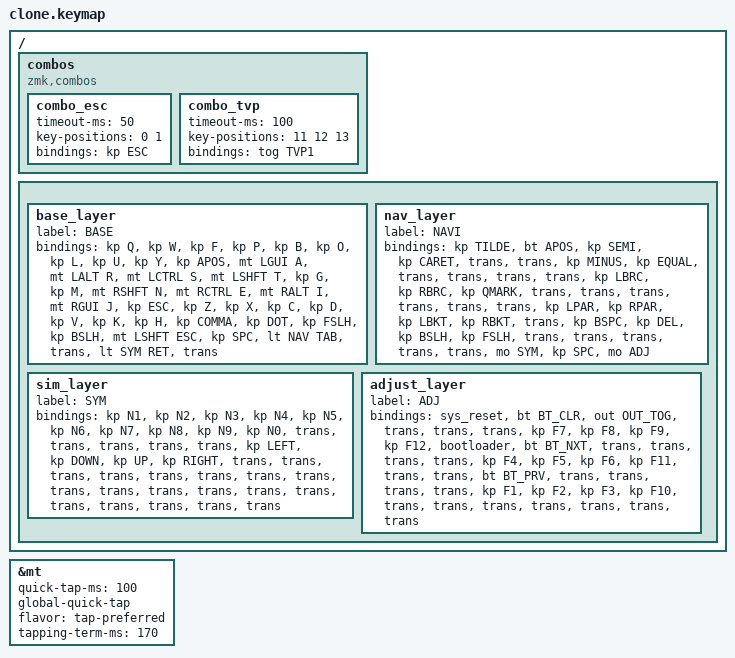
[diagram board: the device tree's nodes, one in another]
#include <behaviors.dtsi>
#include <dt-bindings/zmk/keys.h>
#include <dt-bindings/zmk/bt.h>
#include <dt-bindings/zmk/outputs.h>

#define BASE 0
#define NAV  1
#define SYM  2
#define ADJ  3
#define TVP1 4
#define TVP2 5

&mt {
    quick-tap-ms = <100>;
    global-quick-tap;
    flavor = "tap-preferred";
    tapping-term-ms = <170>;
};

/ {
    combos {
        compatible = "zmk,combos";
        combo_esc {
            timeout-ms = <50>;
            key-positions = <0 1>;
            bindings = <&kp ESC>;
        };
        combo_tvp {
            timeout-ms = <100>;
            key-positions = <11 12 13>;
            bindings = <&tog TVP1>;
        };
    };
    {
        base_layer {
            label= "BASE";

            //             ┏━━━━━━━━━━━┳━━━━━━━━━━━┳━━━━━━━━━━━┳━━━━━━━━━━━┳━━━━━━━━━━━┓   ┏━━━━━━━━━━━┳━━━━━━━━━━━┳━━━━━━━━━━━┳━━━━━━━━━━━┳━━━━━━━━━━━┓
            //             ┃     Q     ┃     W     ┃     F     ┃     P     ┃     B     ┃   ┃     O     ┃     L     ┃     U     ┃     Y     ┃    '/"    ┃
            //             ┣━━━━━━━━━━━╋━━━━━━━━━━━╋━━━━━━━━━━━╋━━━━━━━━━━━╋━━━━━━━━━━━┫   ┣━━━━━━━━━━━╋━━━━━━━━━━━╋━━━━━━━━━━━╋━━━━━━━━━━━╋━━━━━━━━━━━┫
            //             ┃     A     ┃     R     ┃     S     ┃     T     ┃     G     ┃   ┃     M     ┃     N     ┃     E     ┃     I     ┃     J     ┃
            // ┏━━━━━━━━━━━╋━━━━━━━━━━━╋━━━━━━━━━━━╋━━━━━━━━━━━╋━━━━━━━━━━━╋━━━━━━━━━━━┫   ┣━━━━━━━━━━━╋━━━━━━━━━━━╋━━━━━━━━━━━╋━━━━━━━━━━━╋━━━━━━━━━━━╋━━━━━━━━━━━┓
            // ┃    ESC    ┃     Z     ┃     X     ┃     C     ┃     D     ┃     V     ┃   ┃     K     ┃     H     ┃     ,     ┃     .     ┃     /     ┃     \     ┃
            // ┗━━━━━━━━━━━┻━━━━━━━━━━━┻━━━━━━━━━━━╋━━━━━━━━━━━╋━━━━━━━━━━━╋━━━━━━━━━━━┫   ┣━━━━━━━━━━━╋━━━━━━━━━━━╋━━━━━━━━━━━╋━━━━━━━━━━━┻━━━━━━━━━━━┻━━━━━━━━━━━┛
            //                                     ┃ LSHFT/ESC ┃    SPC    ┃   /TAB    ┃   ┃           ┃   /RET    ┃           ┃
            //                                     ┗━━━━━━━━━━━┻━━━━━━━━━━━┻━━━━━━━━━━━┛   ┗━━━━━━━━━━━┻━━━━━━━━━━━┻━━━━━━━━━━━┛
            bindings = <

                // ╷           ╷           ╷           ╷           ╷           ╷           ╷   ╷           ╷           ╷           ╷           ╷           ╷           ╷

                               &kp Q       &kp W       &kp F       &kp P       &kp B           &kp O       &kp L       &kp U       &kp Y       &kp APOS
                               &mt LGUI A  &mt LALT R  &mt LCTRL S &mt LSHFT T &kp G           &kp M       &mt RSHFT N &mt RCTRL E &mt RALT I  &mt RGUI J
                   &kp ESC     &kp Z       &kp X       &kp C       &kp D       &kp V           &kp K       &kp H       &kp COMMA   &kp DOT     &kp FSLH    &kp BSLH
                                                     &mt LSHFT ESC &kp SPC     &lt NAV TAB     &trans      &lt SYM RET &trans
            >;
        };

        nav_layer {
            label= "NAVI";

            //             ┏━━━━━━━━━━━┳━━━━━━━━━━━┳━━━━━━━━━━━┳━━━━━━━━━━━┳━━━━━━━━━━━┓   ┏━━━━━━━━━━━┳━━━━━━━━━━━┳━━━━━━━━━━━┳━━━━━━━━━━━┳━━━━━━━━━━━┓
            //             ┃     ~     ┃    '/"    ┃    ;/:    ┃     ^     ┃           ┃   ┃           ┃    -/_    ┃    =/+    ┃           ┃           ┃
            //             ┣━━━━━━━━━━━╋━━━━━━━━━━━╋━━━━━━━━━━━╋━━━━━━━━━━━╋━━━━━━━━━━━┫   ┣━━━━━━━━━━━╋━━━━━━━━━━━╋━━━━━━━━━━━╋━━━━━━━━━━━╋━━━━━━━━━━━┫
            //             ┃           ┃           ┃     {     ┃     }     ┃     ?     ┃   ┃           ┃           ┃           ┃           ┃           ┃
            // ┏━━━━━━━━━━━╋━━━━━━━━━━━╋━━━━━━━━━━━╋━━━━━━━━━━━╋━━━━━━━━━━━╋━━━━━━━━━━━┫   ┣━━━━━━━━━━━╋━━━━━━━━━━━╋━━━━━━━━━━━╋━━━━━━━━━━━╋━━━━━━━━━━━╋━━━━━━━━━━━┓
            // ┃           ┃     (     ┃     )     ┃     [     ┃     ]     ┃           ┃   ┃ BACKSPACE ┃  DELETE   ┃     \     ┃     /     ┃           ┃           ┃
            // ┗━━━━━━━━━━━┻━━━━━━━━━━━┻━━━━━━━━━━━╋━━━━━━━━━━━╋━━━━━━━━━━━╋━━━━━━━━━━━┫   ┣━━━━━━━━━━━╋━━━━━━━━━━━╋━━━━━━━━━━━╋━━━━━━━━━━━┻━━━━━━━━━━━┻━━━━━━━━━━━┛
            //                                     ┃           ┃           ┃           ┃   ┃     SYM   ┃   SPACE   ┃    ADJ    ┃
            //                                     ┗━━━━━━━━━━━┻━━━━━━━━━━━┻━━━━━━━━━━━┛   ┗━━━━━━━━━━━┻━━━━━━━━━━━┻━━━━━━━━━━━┛
            bindings = <
                // ╷           ╷           ╷           ╷           ╷           ╷           ╷   ╷           ╷           ╷           ╷           ╷           ╷           ╷

                                &kp TILDE   &bt APOS    &kp SEMI    &kp CARET   &trans          &trans      &kp MINUS   &kp EQUAL   &trans      &trans
                                &trans      &trans      &kp LBRC    &kp RBRC    &kp QMARK       &trans      &trans      &trans      &trans      &trans
                    &trans      &kp LPAR    &kp RPAR    &kp LBKT    &kp RBKT    &trans          &kp BSPC    &kp DEL     &kp BSLH    &kp FSLH    &trans      &trans      
                                                        &trans      &trans      &trans          &mo SYM     &kp SPC     &mo ADJ
            >;
        };

        sim_layer {
            label= "SYM";

            //             ┏━━━━━━━━━━━┳━━━━━━━━━━━┳━━━━━━━━━━━┳━━━━━━━━━━━┳━━━━━━━━━━━┓   ┏━━━━━━━━━━━┳━━━━━━━━━━━┳━━━━━━━━━━━┳━━━━━━━━━━━┳━━━━━━━━━━━┓
            //             ┃     1     ┃     2     ┃     3     ┃     4     ┃     5     ┃   ┃     6     ┃     7     ┃     8     ┃     9     ┃     0     ┃
            //             ┣━━━━━━━━━━━╋━━━━━━━━━━━╋━━━━━━━━━━━╋━━━━━━━━━━━╋━━━━━━━━━━━┫   ┣━━━━━━━━━━━╋━━━━━━━━━━━╋━━━━━━━━━━━╋━━━━━━━━━━━╋━━━━━━━━━━━┫
            //             ┃           ┃           ┃           ┃           ┃           ┃   ┃           ┃           ┃           ┃           ┃           ┃
            // ┏━━━━━━━━━━━╋━━━━━━━━━━━╋━━━━━━━━━━━╋━━━━━━━━━━━╋━━━━━━━━━━━╋━━━━━━━━━━━┫   ┣━━━━━━━━━━━╋━━━━━━━━━━━╋━━━━━━━━━━━╋━━━━━━━━━━━╋━━━━━━━━━━━╋━━━━━━━━━━━┓
            // ┃           ┃           ┃           ┃           ┃           ┃           ┃   ┃           ┃           ┃           ┃           ┃           ┃           ┃
            // ┗━━━━━━━━━━━┻━━━━━━━━━━━┻━━━━━━━━━━━╋━━━━━━━━━━━╋━━━━━━━━━━━╋━━━━━━━━━━━┫   ┣━━━━━━━━━━━╋━━━━━━━━━━━╋━━━━━━━━━━━╋━━━━━━━━━━━┻━━━━━━━━━━━┻━━━━━━━━━━━┛
            //                                     ┃           ┃           ┃           ┃   ┃           ┃           ┃           ┃
            //                                     ┗━━━━━━━━━━━┻━━━━━━━━━━━┻━━━━━━━━━━━┛   ┗━━━━━━━━━━━┻━━━━━━━━━━━┻━━━━━━━━━━━┛
            bindings = <
                // ╷           ╷           ╷           ╷           ╷           ╷           ╷   ╷           ╷           ╷           ╷           ╷           ╷           ╷

                &kp N1      &kp N2      &kp N3      &kp N4      &kp N5          &kp N6      &kp N7      &kp N8      &kp N9      &kp N0       
                &trans      &trans      &trans      &trans      &trans          &kp LEFT    &kp DOWN    &kp UP      &kp RIGHT   &trans 
                &trans      &trans      &trans      &trans      &trans      &trans          &trans      &trans      &trans      &trans      &trans      &trans         
                &trans      &trans      &trans          &trans      &trans      &trans      
            >;
        };

        adjust_layer {
            label= "ADJ";

            //             ┏━━━━━━━━━━━┳━━━━━━━━━━━┳━━━━━━━━━━━┳━━━━━━━━━━━┳━━━━━━━━━━━┓   ┏━━━━━━━━━━━┳━━━━━━━━━━━┳━━━━━━━━━━━┳━━━━━━━━━━━┳━━━━━━━━━━━┓
            //             ┃   RESET   ┃ BT CLEAR  ┃  OUT TOG  ┃           ┃           ┃   ┃           ┃    F7     ┃    F8     ┃    F9     ┃    F12    ┃
            //             ┣━━━━━━━━━━━╋━━━━━━━━━━━╋━━━━━━━━━━━╋━━━━━━━━━━━╋━━━━━━━━━━━┫   ┣━━━━━━━━━━━╋━━━━━━━━━━━╋━━━━━━━━━━━╋━━━━━━━━━━━╋━━━━━━━━━━━┫
            //             ┃ BOOTLOAD  ┃ BT NEXT   ┃           ┃           ┃           ┃   ┃           ┃    F4     ┃    F5     ┃    F6     ┃    F11    ┃
            // ┏━━━━━━━━━━━╋━━━━━━━━━━━╋━━━━━━━━━━━╋━━━━━━━━━━━╋━━━━━━━━━━━╋━━━━━━━━━━━┫   ┣━━━━━━━━━━━╋━━━━━━━━━━━╋━━━━━━━━━━━╋━━━━━━━━━━━╋━━━━━━━━━━━╋━━━━━━━━━━━┓
            // ┃           ┃           ┃ BT PREV   ┃           ┃           ┃           ┃   ┃           ┃    F1     ┃    F2     ┃    F3     ┃    F10    ┃           ┃
            // ┗━━━━━━━━━━━┻━━━━━━━━━━━┻━━━━━━━━━━━╋━━━━━━━━━━━╋━━━━━━━━━━━╋━━━━━━━━━━━┫   ┣━━━━━━━━━━━╋━━━━━━━━━━━╋━━━━━━━━━━━╋━━━━━━━━━━━┻━━━━━━━━━━━┻━━━━━━━━━━━┛
            //                                     ┃           ┃           ┃           ┃   ┃           ┃           ┃           ┃
            //                                     ┗━━━━━━━━━━━┻━━━━━━━━━━━┻━━━━━━━━━━━┛   ┗━━━━━━━━━━━┻━━━━━━━━━━━┻━━━━━━━━━━━┛
            bindings = <
                // ╷           ╷           ╷           ╷           ╷           ╷           ╷   ╷           ╷           ╷           ╷           ╷           ╷           ╷

                &sys_reset  &bt BT_CLR  &out OUT_TOG &trans      &trans          &trans      &kp F7      &kp F8      &kp F9      &kp F12
                &bootloader &bt BT_NXT  &trans       &trans      &trans          &trans      &kp F4      &kp F5      &kp F6      &kp F11  
                &trans      &trans      &bt BT_PRV  &trans       &trans      &trans          &trans      &kp F1      &kp F2      &kp F3      &kp F10     &trans         
                &trans       &trans      &trans          &trans      &trans      &trans      
            >;
        };
    };
};
